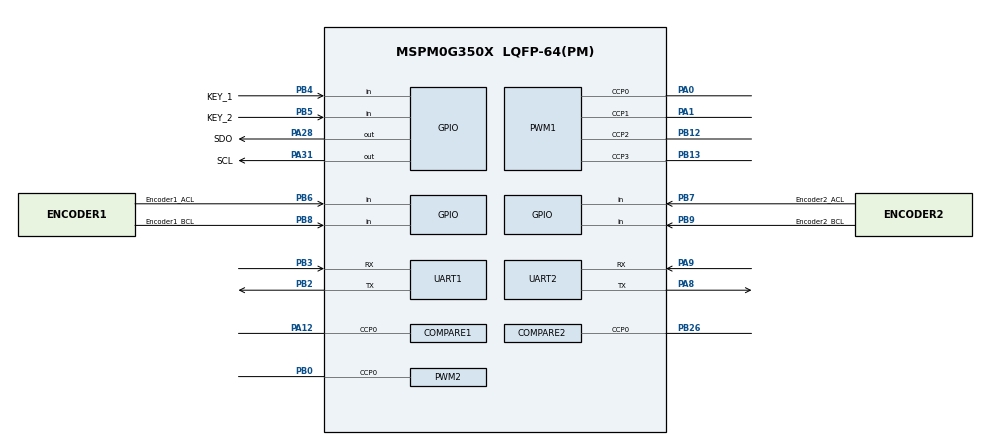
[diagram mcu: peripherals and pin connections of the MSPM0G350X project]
/**
 * @cliArgs --device "MSPM0G350X" --part "Default" --package "LQFP-64(PM)" --product "mspm0_sdk@2.10.00.04"
 * @versions {"tool":"1.26.2+4477"}
 */

/**
 * Import the modules used in this configuration.
 */
const ADC12    = scripting.addModule("/ti/driverlib/ADC12", {}, false);
const ADC121   = ADC12.addInstance();
const ADC122   = ADC12.addInstance();
const COMPARE  = scripting.addModule("/ti/driverlib/COMPARE", {}, false);
const COMPARE1 = COMPARE.addInstance();
const COMPARE2 = COMPARE.addInstance();
const GPIO     = scripting.addModule("/ti/driverlib/GPIO", {}, false);
const GPIO1    = GPIO.addInstance();
const GPIO2    = GPIO.addInstance();
const GPIO3    = GPIO.addInstance();
const GPIO4    = GPIO.addInstance();
const GPIO5    = GPIO.addInstance();
const GPIO6    = GPIO.addInstance();
const GPIO7    = GPIO.addInstance();
const PWM      = scripting.addModule("/ti/driverlib/PWM", {}, false);
const PWM1     = PWM.addInstance();
const PWM2     = PWM.addInstance();
const SYSCTL   = scripting.addModule("/ti/driverlib/SYSCTL");
const SYSTICK  = scripting.addModule("/ti/driverlib/SYSTICK");
const UART     = scripting.addModule("/ti/driverlib/UART", {}, false);
const UART1    = UART.addInstance();
const UART2    = UART.addInstance();
const VREF     = scripting.addModule("/ti/driverlib/VREF");

/**
 * Write custom configuration values to the imported modules.
 */
const divider9       = system.clockTree["UDIV"];
divider9.divideValue = 2;

const mux4       = system.clockTree["EXHFMUX"];
mux4.inputSelect = "EXHFMUX_XTAL";

const mux5       = system.clockTree["EXLFMUX"];
mux5.inputSelect = "EXLFMUX_XTAL";

const mux8       = system.clockTree["HSCLKMUX"];
mux8.inputSelect = "HSCLKMUX_SYSPLL2X";

const mux12       = system.clockTree["SYSPLLMUX"];
mux12.inputSelect = "zSYSPLLMUX_HFCLK";

const pinFunction4       = system.clockTree["HFXT"];
pinFunction4.inputFreq   = 40;
pinFunction4.enable      = true;
pinFunction4.HFXTStartup = 10;

const pinFunction6     = system.clockTree["LFXT"];
pinFunction6.inputFreq = 32.768;
pinFunction6.enable    = true;

ADC121.$name               = "ADC12_0";
ADC121.enableDMA           = false;
ADC121.sampClkSrc          = "DL_ADC12_CLOCK_ULPCLK";
ADC121.enabledInterrupts   = ["DL_ADC12_INTERRUPT_MEM0_RESULT_LOADED"];
ADC121.adcMem7chansel      = "DL_ADC12_INPUT_CHAN_7";
ADC121.adcMem0chansel      = "DL_ADC12_INPUT_CHAN_7";
ADC121.powerDownMode       = "DL_ADC12_POWER_DOWN_MODE_MANUAL";
ADC121.sampleTime0         = "125ns";
ADC121.peripheral.$assign  = "ADC0";
ADC121.adcPin7Config.$name = "ti_driverlib_gpio_GPIOPinGeneric3";

ADC122.$name                 = "ADC12_1";
ADC122.adcMem0chansel        = "DL_ADC12_INPUT_CHAN_12";
ADC122.adcMem1chansel        = "DL_ADC12_INPUT_CHAN_15";
ADC122.adcMem1vref           = "VREF";
ADC122.enabledInterrupts     = ["DL_ADC12_INTERRUPT_MEM0_RESULT_LOADED","DL_ADC12_INTERRUPT_MEM1_RESULT_LOADED"];
ADC122.samplingOperationMode = "sequence";
ADC122.endAdd                = 1;
ADC122.disChan12             = true;
ADC122.powerDownMode         = "DL_ADC12_POWER_DOWN_MODE_MANUAL";
ADC122.sampleTime0           = "300us";

const Board = scripting.addModule("/ti/driverlib/Board", {}, false);

COMPARE1.compareMode                        = "EDGE_COUNT_UP";
COMPARE1.$name                              = "Encoder_1";
COMPARE1.timerPeriod                        = 65536;
COMPARE1.peripheral.$assign                 = "TIMG0";
COMPARE1.peripheral.ccp0Pin.$assign         = "PA12";
COMPARE1.ccp0PinConfig.hideOutputInversion  = scripting.forceWrite(false);
COMPARE1.ccp0PinConfig.onlyInternalResistor = scripting.forceWrite(false);
COMPARE1.ccp0PinConfig.passedPeripheralType = scripting.forceWrite("Digital");
COMPARE1.ccp0PinConfig.$name                = "ti_driverlib_gpio_GPIOPinGeneric4";

COMPARE2.$name                              = "Encoder_2";
COMPARE2.compareMode                        = "EDGE_COUNT_UP";
COMPARE2.timerPeriod                        = 65536;
COMPARE2.peripheral.$assign                 = "TIMG6";
COMPARE2.peripheral.ccp0Pin.$assign         = "PB26";
COMPARE2.ccp0PinConfig.hideOutputInversion  = scripting.forceWrite(false);
COMPARE2.ccp0PinConfig.onlyInternalResistor = scripting.forceWrite(false);
COMPARE2.ccp0PinConfig.passedPeripheralType = scripting.forceWrite("Digital");
COMPARE2.ccp0PinConfig.$name                = "ti_driverlib_gpio_GPIOPinGeneric2";

GPIO1.$name                              = "OLED_IIC";
GPIO1.port                               = "PORTA";
GPIO1.portSegment                        = "Upper";
GPIO1.associatedPins.create(2);
GPIO1.associatedPins[0].$name            = "SCL";
GPIO1.associatedPins[0].initialValue     = "SET";
GPIO1.associatedPins[0].internalResistor = "PULL_UP";
GPIO1.associatedPins[0].assignedPin      = "31";
GPIO1.associatedPins[0].pin.$assign      = "PA31";
GPIO1.associatedPins[1].$name            = "SDO";
GPIO1.associatedPins[1].initialValue     = "SET";
GPIO1.associatedPins[1].internalResistor = "PULL_UP";
GPIO1.associatedPins[1].assignedPin      = "28";
GPIO1.associatedPins[1].pin.$assign      = "PA28";

GPIO2.port                               = "PORTB";
GPIO2.$name                              = "KEY";
GPIO2.associatedPins.create(2);
GPIO2.associatedPins[0].$name            = "KEY_1";
GPIO2.associatedPins[0].direction        = "INPUT";
GPIO2.associatedPins[0].assignedPin      = "4";
GPIO2.associatedPins[0].internalResistor = "PULL_UP";
GPIO2.associatedPins[0].pin.$assign      = "PB4";
GPIO2.associatedPins[1].$name            = "KEY_2";
GPIO2.associatedPins[1].direction        = "INPUT";
GPIO2.associatedPins[1].assignedPin      = "5";
GPIO2.associatedPins[1].internalResistor = "PULL_UP";
GPIO2.associatedPins[1].pin.$assign      = "PB5";

GPIO3.$name                              = "Encoder1";
GPIO3.port                               = "PORTB";
GPIO3.associatedPins.create(2);
GPIO3.associatedPins[0].direction        = "INPUT";
GPIO3.associatedPins[0].interruptEn      = true;
GPIO3.associatedPins[0].polarity         = "FALL";
GPIO3.associatedPins[0].$name            = "Encoder1_ACL";
GPIO3.associatedPins[0].assignedPin      = "6";
GPIO3.associatedPins[0].internalResistor = "PULL_UP";
GPIO3.associatedPins[0].pin.$assign      = "PB6";
GPIO3.associatedPins[1].direction        = "INPUT";
GPIO3.associatedPins[1].$name            = "Encoder1_BCL";
GPIO3.associatedPins[1].assignedPin      = "8";
GPIO3.associatedPins[1].internalResistor = "PULL_UP";
GPIO3.associatedPins[1].pin.$assign      = "PB8";

GPIO4.$name                              = "Encoder2";
GPIO4.port                               = "PORTB";
GPIO4.associatedPins.create(2);
GPIO4.associatedPins[0].direction        = "INPUT";
GPIO4.associatedPins[0].interruptEn      = true;
GPIO4.associatedPins[0].polarity         = "FALL";
GPIO4.associatedPins[0].$name            = "Encoder2_ACL";
GPIO4.associatedPins[0].assignedPin      = "7";
GPIO4.associatedPins[0].internalResistor = "PULL_UP";
GPIO4.associatedPins[0].pin.$assign      = "PB7";
GPIO4.associatedPins[1].direction        = "INPUT";
GPIO4.associatedPins[1].$name            = "Encoder2_BCL";
GPIO4.associatedPins[1].assignedPin      = "9";
GPIO4.associatedPins[1].internalResistor = "PULL_UP";
GPIO4.associatedPins[1].pin.$assign      = "PB9";

GPIO5.$name                                 = "BUZZER";
GPIO5.associatedPins[0].$name               = "BUZZER_1";
GPIO5.associatedPins[0].assignedPortSegment = "Lower";
GPIO5.associatedPins[0].assignedPort        = "PORTB";
GPIO5.associatedPins[0].assignedPin         = "10";

GPIO6.$name                          = "Linepatrol";
GPIO6.associatedPins.create(7);
GPIO6.associatedPins[0].$name        = "Linepatrol_1";
GPIO6.associatedPins[0].direction    = "INPUT";
GPIO6.associatedPins[0].assignedPort = "PORTA";
GPIO6.associatedPins[0].assignedPin  = "27";
GPIO6.associatedPins[1].$name        = "Linepatrol_2";
GPIO6.associatedPins[1].direction    = "INPUT";
GPIO6.associatedPins[1].assignedPort = "PORTA";
GPIO6.associatedPins[1].assignedPin  = "26";
GPIO6.associatedPins[2].$name        = "Linepatrol_3";
GPIO6.associatedPins[2].assignedPort = "PORTA";
GPIO6.associatedPins[2].assignedPin  = "25";
GPIO6.associatedPins[2].direction    = "INPUT";
GPIO6.associatedPins[3].$name        = "Linepatrol_4";
GPIO6.associatedPins[3].assignedPort = "PORTA";
GPIO6.associatedPins[3].assignedPin  = "24";
GPIO6.associatedPins[3].direction    = "INPUT";
GPIO6.associatedPins[4].$name        = "Linepatrol_5";
GPIO6.associatedPins[4].direction    = "INPUT";
GPIO6.associatedPins[4].assignedPort = "PORTB";
GPIO6.associatedPins[4].assignedPin  = "25";
GPIO6.associatedPins[5].$name        = "Linepatrol_6";
GPIO6.associatedPins[5].assignedPort = "PORTB";
GPIO6.associatedPins[5].direction    = "INPUT";
GPIO6.associatedPins[5].assignedPin  = "24";
GPIO6.associatedPins[6].direction    = "INPUT";
GPIO6.associatedPins[6].$name        = "Linepatrol_7";
GPIO6.associatedPins[6].assignedPort = "PORTB";
GPIO6.associatedPins[6].assignedPin  = "20";

GPIO7.$name                          = "StepMotor_CTRL";
GPIO7.associatedPins[0].$name        = "StepMotor_1_CTRL";
GPIO7.associatedPins[0].initialValue = "SET";
GPIO7.associatedPins[0].assignedPort = "PORTA";
GPIO7.associatedPins[0].assignedPin  = "30";

PWM1.$name                      = "PWM_0";
PWM1.pwmMode                    = "EDGE_ALIGN_UP";
PWM1.timerCount                 = 10000;
PWM1.ccIndex                    = [0,1,2,3];
PWM1.PWM_CHANNEL_0.$name        = "ti_driverlib_pwm_PWMTimerCC0";
PWM1.PWM_CHANNEL_1.$name        = "ti_driverlib_pwm_PWMTimerCC1";
PWM1.ccp0PinConfig.$name        = "ti_driverlib_gpio_GPIOPinGeneric0";
PWM1.ccp0PinConfig.enableConfig = true;
PWM1.ccp1PinConfig.$name        = "ti_driverlib_gpio_GPIOPinGeneric1";
PWM1.peripheral.$assign         = "TIMA0";
PWM1.peripheral.ccp0Pin.$assign = "PA0";
PWM1.peripheral.ccp1Pin.$assign = "PA1";
PWM1.peripheral.ccp2Pin.$assign = "PB12";
PWM1.peripheral.ccp3Pin.$assign = "PB13";
PWM1.PWM_CHANNEL_2.$name        = "ti_driverlib_pwm_PWMTimerCC4";
PWM1.PWM_CHANNEL_3.$name        = "ti_driverlib_pwm_PWMTimerCC5";
PWM1.ccp2PinConfig.$name        = "ti_driverlib_gpio_GPIOPinGeneric6";
PWM1.ccp3PinConfig.$name        = "ti_driverlib_gpio_GPIOPinGeneric7";

PWM2.$name                              = "StepMotor";
PWM2.ccIndex                            = [0];
PWM2.pwmMode                            = "EDGE_ALIGN_UP";
PWM2.clockPrescale                      = 80;
PWM2.interrupts                         = ["LOAD_EVENT"];
PWM2.PWM_CHANNEL_0.$name                = "ti_driverlib_pwm_PWMTimerCC2";
PWM2.PWM_CHANNEL_0.dutyCycle            = 10;
PWM2.PWM_CHANNEL_0.ccValue              = 100;
PWM2.ccp0PinConfig.direction            = scripting.forceWrite("OUTPUT");
PWM2.ccp0PinConfig.hideOutputInversion  = scripting.forceWrite(false);
PWM2.ccp0PinConfig.onlyInternalResistor = scripting.forceWrite(false);
PWM2.ccp0PinConfig.passedPeripheralType = scripting.forceWrite("Digital");
PWM2.ccp0PinConfig.$name                = "ti_driverlib_gpio_GPIOPinGeneric8";
PWM2.peripheral.$assign                 = "TIMA1";
PWM2.peripheral.ccp0Pin.$assign         = "PB0";

SYSCTL.clockTreeEn = true;

SYSTICK.periodEnable    = true;
SYSTICK.interruptEnable = true;
SYSTICK.systickEnable   = true;
SYSTICK.period          = 80000;

UART1.$name                                = "UART_0";
UART1.targetBaudRate                       = 115200;
UART1.enableFIFO                           = true;
UART1.rxFifoThreshold                      = "DL_UART_RX_FIFO_LEVEL_ONE_ENTRY";
UART1.enableDMATX                          = false;
UART1.enabledDMARXTriggers                 = "DL_UART_DMA_INTERRUPT_RX";
UART1.peripheral.$assign                   = "UART3";
UART1.peripheral.rxPin.$assign             = "PB3";
UART1.peripheral.txPin.$assign             = "PB2";
UART1.txPinConfig.$name                    = "ti_driverlib_gpio_GPIOPinGeneric9";
UART1.rxPinConfig.$name                    = "ti_driverlib_gpio_GPIOPinGeneric10";
UART1.rxPinConfig.internalResistor         = "PULL_DOWN";
UART1.DMA_CHANNEL_RX.$name                 = "DMA_CH0";
UART1.DMA_CHANNEL_RX.addressMode           = "f2b";
UART1.DMA_CHANNEL_RX.srcLength             = "BYTE";
UART1.DMA_CHANNEL_RX.dstLength             = "BYTE";
UART1.DMA_CHANNEL_RX.configureTransferSize = true;
UART1.DMA_CHANNEL_RX.transferMode          = "FULL_CH_REPEAT_SINGLE";
UART1.DMA_CHANNEL_RX.transferSize          = 36;

UART2.$name                            = "video";
UART2.targetBaudRate                   = 115200;
UART2.enabledInterrupts                = ["RX"];
UART2.peripheral.$assign               = "UART1";
UART2.peripheral.rxPin.$assign         = "PA9";
UART2.peripheral.txPin.$assign         = "PA8";
UART2.txPinConfig.direction            = scripting.forceWrite("OUTPUT");
UART2.txPinConfig.hideOutputInversion  = scripting.forceWrite(false);
UART2.txPinConfig.onlyInternalResistor = scripting.forceWrite(false);
UART2.txPinConfig.passedPeripheralType = scripting.forceWrite("Digital");
UART2.txPinConfig.$name                = "ti_driverlib_gpio_GPIOPinGeneric11";
UART2.rxPinConfig.hideOutputInversion  = scripting.forceWrite(false);
UART2.rxPinConfig.onlyInternalResistor = scripting.forceWrite(false);
UART2.rxPinConfig.passedPeripheralType = scripting.forceWrite("Digital");
UART2.rxPinConfig.$name                = "ti_driverlib_gpio_GPIOPinGeneric12";

VREF.basicIntVolt           = "DL_VREF_BUFCONFIG_OUTPUT_2_5V";
VREF.vrefPosPinConfig.$name = "ti_driverlib_gpio_GPIOPinGeneric5";

/**
 * Pinmux solution for unlocked pins/peripherals. This ensures that minor changes to the automatic solver in a future
 * version of the tool will not impact the pinmux you originally saw.  These lines can be completely deleted in order to
 * re-solve from scratch.
 */
pinFunction4.peripheral.$suggestSolution           = "SYSCTL";
pinFunction4.peripheral.hfxInPin.$suggestSolution  = "PA5";
pinFunction4.peripheral.hfxOutPin.$suggestSolution = "PA6";
pinFunction6.peripheral.$suggestSolution           = "SYSCTL";
pinFunction6.peripheral.lfxInPin.$suggestSolution  = "PA3";
pinFunction6.peripheral.lfxOutPin.$suggestSolution = "PA4";
ADC121.peripheral.adcPin7.$suggestSolution         = "PA22";
ADC122.peripheral.$suggestSolution                 = "ADC1";
Board.peripheral.$suggestSolution                  = "DEBUGSS";
Board.peripheral.swclkPin.$suggestSolution         = "PA20";
Board.peripheral.swdioPin.$suggestSolution         = "PA19";
GPIO5.associatedPins[0].pin.$suggestSolution       = "PB10";
GPIO6.associatedPins[0].pin.$suggestSolution       = "PA27";
GPIO6.associatedPins[1].pin.$suggestSolution       = "PA26";
GPIO6.associatedPins[2].pin.$suggestSolution       = "PA25";
GPIO6.associatedPins[3].pin.$suggestSolution       = "PA24";
GPIO6.associatedPins[4].pin.$suggestSolution       = "PB25";
GPIO6.associatedPins[5].pin.$suggestSolution       = "PB24";
GPIO6.associatedPins[6].pin.$suggestSolution       = "PB20";
GPIO7.associatedPins[0].pin.$suggestSolution       = "PA30";
UART1.DMA_CHANNEL_RX.peripheral.$suggestSolution   = "DMA_CH0";
VREF.peripheral.$suggestSolution                   = "VREF";
VREF.peripheral.vrefPosPin.$suggestSolution        = "PA23";
